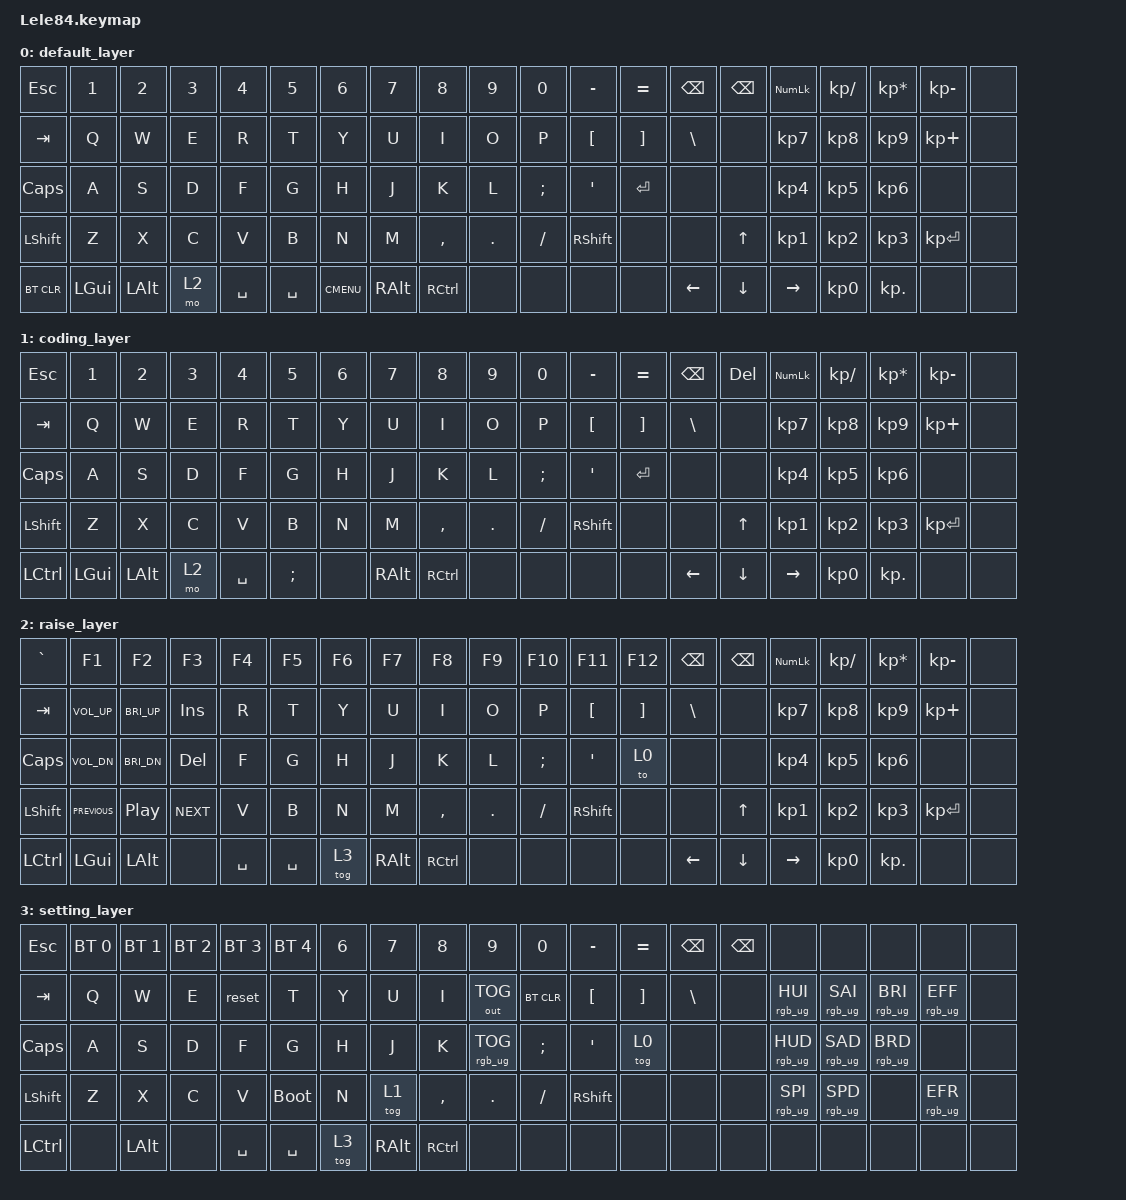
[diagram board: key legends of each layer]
#include <behaviors.dtsi>
#include <dt-bindings/zmk/keys.h>
#include <dt-bindings/zmk/bt.h>
#include <dt-bindings/zmk/outputs.h>
#include <dt-bindings/zmk/rgb.h>

/ {
    keymap {
        compatible = "zmk,keymap";

        default_layer {

            bindings = <
&kp ESC &kp N1 &kp N2 &kp N3 &kp N4 &kp N5 &kp N6 &kp N7 &kp   N8  &kp  N9 &kp  N0  &kp MINUS &kp EQUAL &kp BSPC  &kp BSPC                             &kp KP_NUMLOCK &kp KP_DIVIDE &kp KP_MULTIPLY &kp KP_MINUS    &none
&kp TAB  &kp Q  &kp W  &kp E  &kp R  &kp T  &kp Y  &kp U  &kp   I   &kp  O  &kp   P  &kp LBKT &kp RBKT  &kp BSLH  &none                                  &kp KP_NUMBER_7 &kp KP_NUMBER_8 &kp KP_NUMBER_9 &kp KP_PLUS  &none
&kp CLCK  &kp A  &kp S  &kp D  &kp F  &kp G  &kp H  &kp J  &kp   K   &kp  L  &kp SEMI &kp SQT     &kp RET   &none  &none                                 &kp KP_NUMBER_4 &kp KP_NUMBER_5 &kp KP_NUMBER_6 &none        &none
&kp LSHFT  &kp Z  &kp X  &kp C  &kp V  &kp B  &kp N  &kp M  &kp COMMA &kp DOT &kp FSLH   &kp RSHFT  &none  &none                         &kp UP_ARROW    &kp KP_NUMBER_1 &kp KP_NUMBER_2 &kp KP_NUMBER_3 &kp KP_ENTER &none
&bt BT_CLR &kp LGUI &kp LALT  &mo 2  &kp SPACE    &kp SPACE   &kp K_CMENU  &kp  RALT  &kp  RCTRL &none  &none &none  &none&kp LEFT_ARROW   &kp DOWN_ARROW   &kp RIGHT_ARROW &kp KP_NUMBER_0 &kp KP_DOT &none            &none
			>;
        };

        
        coding_layer {

            bindings = <
&kp ESC &kp N1 &kp N2 &kp N3 &kp N4 &kp N5 &kp N6 &kp N7 &kp   N8  &kp  N9 &kp  N0  &kp MINUS &kp EQUAL &kp BSPC  &kp DELETE                             &kp KP_NUMLOCK &kp KP_DIVIDE &kp KP_MULTIPLY &kp KP_MINUS    &none
&kp TAB  &kp Q  &kp W  &kp E  &kp R  &kp T  &kp Y  &kp U  &kp   I   &kp  O  &kp   P  &kp LBKT &kp RBKT  &kp BSLH  &none                                  &kp KP_NUMBER_7 &kp KP_NUMBER_8 &kp KP_NUMBER_9 &kp KP_PLUS  &none
&kp CLCK  &kp A  &kp S  &kp D  &kp F  &kp G  &kp H  &kp J  &kp   K   &kp  L  &kp SEMI &kp SQT     &kp RET   &none  &none                                 &kp KP_NUMBER_4 &kp KP_NUMBER_5 &kp KP_NUMBER_6 &none        &none
&kp LSHFT  &kp Z  &kp X  &kp C  &kp V  &kp B  &kp N  &kp M  &kp COMMA &kp DOT &kp FSLH   &kp RSHFT  &none  &none                         &kp UP_ARROW    &kp KP_NUMBER_1 &kp KP_NUMBER_2 &kp KP_NUMBER_3 &kp KP_ENTER &none
&kp LCTRL &kp LGUI &kp LALT  &mo 2  &kp SPACE    &kp SEMI   &none    &kp  RALT  &kp  RCTRL &none  &none &none  &none&kp LEFT_ARROW   &kp DOWN_ARROW   &kp RIGHT_ARROW &kp KP_NUMBER_0 &kp KP_DOT &none            &none
			>;
        };

        raise_layer {

            bindings = <
&kp GRAV &kp F1 &kp F2 &kp F3 &kp F4 &kp F5 &kp F6 &kp F7 &kp   F8  &kp  F9 &kp  F10  &kp F11 &kp F12 &kp BSPC  &kp BSPC                                               &kp KP_NUMLOCK &kp KP_DIVIDE &kp KP_MULTIPLY &kp KP_MINUS    &none
&kp TAB  &kp C_VOL_UP  &kp C_BRI_UP  &kp INS  &kp R  &kp T  &kp Y  &kp U  &kp   I   &kp  O  &kp   P  &kp LBKT &kp RBKT  &kp BSLH  &none                                  &kp KP_NUMBER_7 &kp KP_NUMBER_8 &kp KP_NUMBER_9 &kp KP_PLUS  &none
&kp CLCK  &kp C_VOL_DN  &kp C_BRI_DN  &kp DEL  &kp F  &kp G  &kp H  &kp J  &kp   K   &kp  L  &kp SEMI &kp SQT     &to 0   &none  &none                                 &kp KP_NUMBER_4 &kp KP_NUMBER_5 &kp KP_NUMBER_6 &none        &none
&kp LSHFT  &kp C_PREVIOUS  &kp C_PLAY_PAUSE  &kp C_NEXT  &kp V  &kp B  &kp N  &kp M  &kp COMMA &kp DOT &kp FSLH   &kp RSHFT  &none  &none                         &kp UP_ARROW    &kp KP_NUMBER_1 &kp KP_NUMBER_2 &kp KP_NUMBER_3 &kp KP_ENTER &none
&kp LCTRL &kp LGUI &kp LALT  &none  &kp SPACE    &kp SPACE   &tog 3      &kp  RALT  &kp  RCTRL &none  &none &none  &none&kp LEFT_ARROW   &kp DOWN_ARROW   &kp RIGHT_ARROW &kp KP_NUMBER_0 &kp KP_DOT &none            &none
			>;
        };

        setting_layer {

            bindings = <
&kp ESC &bt BT_SEL 0 &bt BT_SEL 1 &bt BT_SEL 2 &bt BT_SEL 3 &bt BT_SEL 4 &kp N6 &kp N7 &kp   N8  &kp  N9 &kp  N0  &kp MINUS &kp EQUAL &kp BSPC  &kp BSPC                             &none &none &none &none      &none
&kp TAB  &kp Q  &kp W  &kp E  &reset  &kp T  &kp Y  &kp U  &kp   I   &out OUT_TOG  &bt BT_CLR  &kp LBKT &kp RBKT  &kp BSLH  &none                                                      &rgb_ug RGB_HUI &rgb_ug RGB_SAI &rgb_ug RGB_BRI &rgb_ug RGB_EFF  &none
&kp CLCK  &kp A  &kp S  &kp D  &kp F  &kp G  &kp H  &kp J  &kp   K   &rgb_ug RGB_TOG &kp SEMI &kp SQT     &tog 0   &none  &none                                                       &rgb_ug RGB_HUD &rgb_ug RGB_SAD &rgb_ug RGB_BRD	 &none          &none
&kp LSHFT  &kp Z  &kp X  &kp C  &kp V  &bootloader  &kp N  &tog 1  &kp COMMA &kp DOT &kp FSLH   &kp RSHFT  &none  &none                                                &none           &rgb_ug RGB_SPI &rgb_ug RGB_SPD &none           &rgb_ug RGB_EFR  &none
&kp LCTRL &none   &kp LALT  &none  &kp SPACE    &kp SPACE   &tog 3     &kp  RALT  &kp  RCTRL &none  &none &none  &none                               &none            &none           &none &none &none &none      &none
			>;
        };

    };
};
